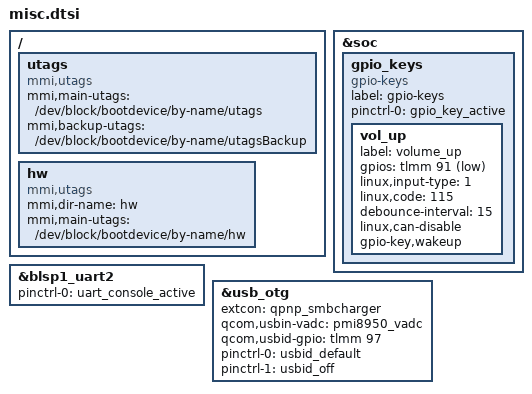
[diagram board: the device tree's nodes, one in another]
/ {
	utags {
		compatible = "mmi,utags";
		mmi,main-utags = "/dev/block/bootdevice/by-name/utags";
		mmi,backup-utags = "/dev/block/bootdevice/by-name/utagsBackup";
	};

	hw {
		compatible = "mmi,utags";
		mmi,dir-name = "hw";
		mmi,main-utags = "/dev/block/bootdevice/by-name/hw";
	};
};

&soc {
	gpio_keys {
		compatible = "gpio-keys";
		label = "gpio-keys";
		pinctrl-names = "default";
		pinctrl-0 = <&gpio_key_active>;

		vol_up {
			label = "volume_up";
			gpios = <&tlmm 91 0x1>;
			linux,input-type = <1>;
			linux,code = <115>;
			debounce-interval = <15>;
			linux,can-disable;
			gpio-key,wakeup;
		};
	};
};

&blsp1_uart2 {
	status = "ok";
	pinctrl-names = "default";
	pinctrl-0 = <&uart_console_active>;
};

&usb_otg {
	extcon = <&qpnp_smbcharger>;
	qcom,usbin-vadc = <&pmi8950_vadc>;
	qcom,usbid-gpio = <&tlmm 97 0>;
	pinctrl-names = "default", "usbid-off";
	pinctrl-0 = <&usbid_default>;
	pinctrl-1 = <&usbid_off>;
};
